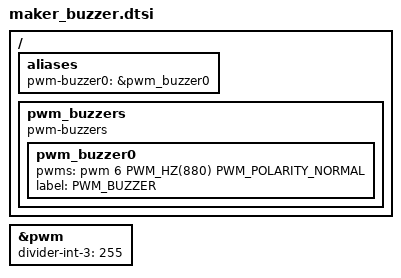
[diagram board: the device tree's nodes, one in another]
/*
 * Copyright (c) 2023-2024 TiaC Systems
 * SPDX-License-Identifier: Apache-2.0
 */

#include <zephyr/dt-bindings/pwm/pwm.h>

/ {
	aliases {
		pwm-buzzer0 = &pwm_buzzer0;
	};

	pwm_buzzers {
		compatible = "pwm-buzzers";
		status = "okay";

		pwm_buzzer0: pwm_buzzer0 {
			pwms = <&pwm 6 PWM_HZ(880) PWM_POLARITY_NORMAL>;
			label = "PWM_BUZZER";
		};
	};
};

&pwm {
	divider-int-3 = <255>;
};
